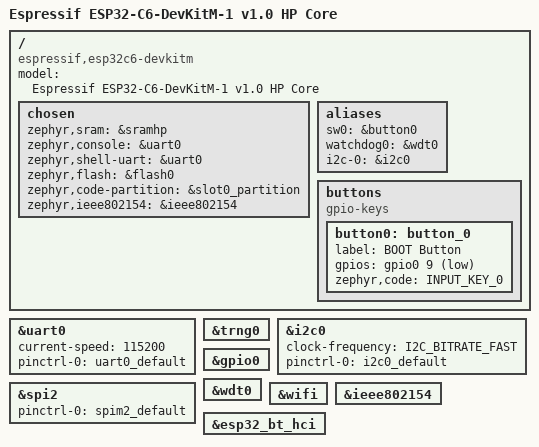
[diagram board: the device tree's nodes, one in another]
/**
 * Espressif ESP32-C6-DevKitM-1 v1.0 (HP Core)
 *
 * Module: ESP32-C6-MINI-1, 4 MB flash
 *
 * SPDX-License-Identifier: Apache-2.0
 */

/dts-v1/;

#include <espressif/esp32c6/esp32c6_wroom_n4.dtsi>
#include "esp32c6_devkitm_hpcore-pinctrl.dtsi"
#include <zephyr/dt-bindings/input/input-event-codes.h>
#include <espressif/partitions_0x0_default.dtsi>

/ {
	model = "Espressif ESP32-C6-DevKitM-1 v1.0 HP Core";
	compatible = "espressif,esp32c6-devkitm";

	chosen {
		zephyr,sram = &sramhp;
		zephyr,console = &uart0;
		zephyr,shell-uart = &uart0;
		zephyr,flash = &flash0;
		zephyr,code-partition = &slot0_partition;
		zephyr,ieee802154 = &ieee802154;
	};

	aliases {
		sw0 = &button0;
		watchdog0 = &wdt0;
		i2c-0 = &i2c0;
	};

	buttons {
		compatible = "gpio-keys";

		button0: button_0 {
			label = "BOOT Button";
			gpios = <&gpio0 9 (GPIO_PULL_UP | GPIO_ACTIVE_LOW)>;
			zephyr,code = <INPUT_KEY_0>;
		};
	};
};

&uart0 {
	status = "okay";
	current-speed = <115200>;
	pinctrl-0 = <&uart0_default>;
	pinctrl-names = "default";
};

/* uart1/twai0 enabled in project overlay for gateway use */

&trng0 {
	status = "okay";
};

&i2c0 {
	status = "okay";
	clock-frequency = <I2C_BITRATE_FAST>;
	pinctrl-0 = <&i2c0_default>;
	pinctrl-names = "default";
};

&spi2 {
	#address-cells = <1>;
	#size-cells = <0>;
	status = "okay";
	pinctrl-0 = <&spim2_default>;
	pinctrl-names = "default";
};

&gpio0 {
	status = "okay";
};

&wdt0 {
	status = "okay";
};

&wifi {
	status = "okay";
};

&ieee802154 {
	status = "okay";
};

&esp32_bt_hci {
	status = "okay";
};
